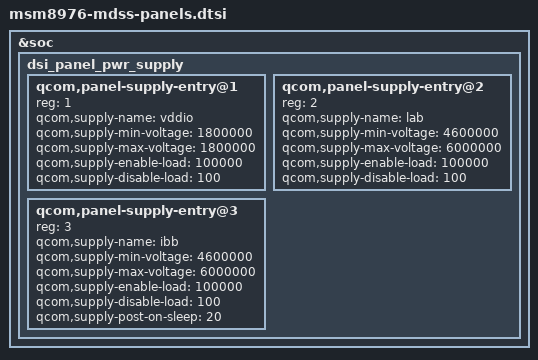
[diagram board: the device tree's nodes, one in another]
/* Copyright (c) 2015, The Linux Foundation. All rights reserved.
 *
 * This program is free software; you can redistribute it and/or modify
 * it under the terms of the GNU General Public License version 2 and
 * only version 2 as published by the Free Software Foundation.
 *
 * This program is distributed in the hope that it will be useful,
 * but WITHOUT ANY WARRANTY; without even the implied warranty of
 * MERCHANTABILITY or FITNESS FOR A PARTICULAR PURPOSE.  See the
 * GNU General Public License for more details.
 */

#include "yulong-dsi-panel-hx8398a-by-auo-fhd-550-video.dtsi"
#include "yulong-dsi-panel-ili9885-lide-auo-fhd-550-video.dtsi"
#include "yulong-dsi-panel-ili9885a-yassy-inl-fhd-550-video.dtsi"
#include "yulong-dsi-panel-nt35532-boyi-auo-fhd-550-video.dtsi"
#include "yulong-dsi-panel-nt35532-boyi-hcg-auo-fhd-550-video.dtsi"
#include "yulong-dsi-panel-nt35532-each-auo-fhd-550-video.dtsi"

&soc {
	dsi_panel_pwr_supply: dsi_panel_pwr_supply {
		#address-cells = <1>;
		#size-cells = <0>;

		qcom,panel-supply-entry@1 {
			reg = <1>;
			qcom,supply-name = "vddio";
			qcom,supply-min-voltage = <1800000>;
			qcom,supply-max-voltage = <1800000>;
			qcom,supply-enable-load = <100000>;
			qcom,supply-disable-load = <100>;
		};

		qcom,panel-supply-entry@2 {
			reg = <2>;
			qcom,supply-name = "lab";
			qcom,supply-min-voltage = <4600000>;
			qcom,supply-max-voltage = <6000000>;
			qcom,supply-enable-load = <100000>;
			qcom,supply-disable-load = <100>;
		};

		qcom,panel-supply-entry@3 {
			reg = <3>;
			qcom,supply-name = "ibb";
			qcom,supply-min-voltage = <4600000>;
			qcom,supply-max-voltage = <6000000>;
			qcom,supply-enable-load = <100000>;
			qcom,supply-disable-load = <100>;
			qcom,supply-post-on-sleep = <20>;
		};
	};
};
